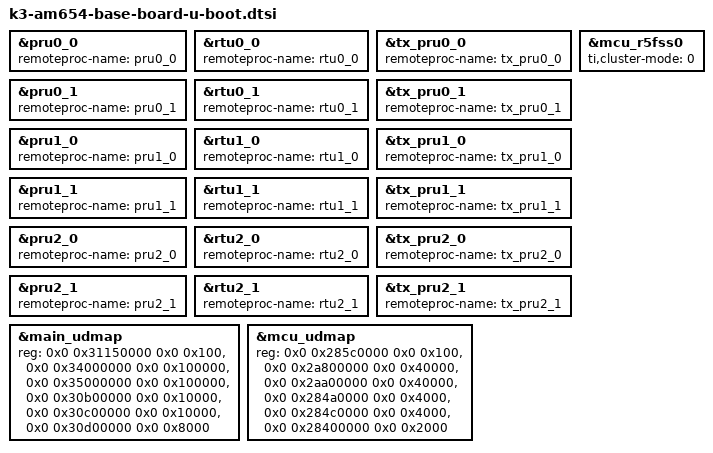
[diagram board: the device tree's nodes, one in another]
// SPDX-License-Identifier: GPL-2.0
/*
 * Copyright (C) 2018-2021 Texas Instruments Incorporated - http://www.ti.com/
 */

#include "k3-am654-r5-base-board-u-boot.dtsi"
#include "k3-am65x-binman.dtsi"

&pru0_0 {
	remoteproc-name = "pru0_0";
};

&rtu0_0 {
	remoteproc-name = "rtu0_0";
};

&tx_pru0_0 {
	remoteproc-name = "tx_pru0_0";
};

&pru0_1 {
	remoteproc-name = "pru0_1";
};

&rtu0_1 {
	remoteproc-name = "rtu0_1";
};

&tx_pru0_1 {
	remoteproc-name = "tx_pru0_1";
};

&pru1_0 {
	remoteproc-name = "pru1_0";
};

&rtu1_0 {
	remoteproc-name = "rtu1_0";
};

&tx_pru1_0 {
	remoteproc-name = "tx_pru1_0";
};

&pru1_1 {
	remoteproc-name = "pru1_1";
};

&rtu1_1 {
	remoteproc-name = "rtu1_1";
};

&tx_pru1_1 {
	remoteproc-name = "tx_pru1_1";
};

&pru2_0 {
	remoteproc-name = "pru2_0";
};

&rtu2_0 {
	remoteproc-name = "rtu2_0";
};

&tx_pru2_0 {
	remoteproc-name = "tx_pru2_0";
};

&pru2_1 {
	remoteproc-name = "pru2_1";
};

&rtu2_1 {
	remoteproc-name = "rtu2_1";
};

&tx_pru2_1 {
	remoteproc-name = "tx_pru2_1";
};

&mcu_r5fss0 {
	ti,cluster-mode = <0>;
};

/*
 * The DMA driver requires a few extra register ranges
 * which are missing for the am65x. A patch has been
 * sent and merged to linux and will be synced with
 * upstream u-boot in the next DT sync.
 */
&main_udmap {
	reg = <0x0 0x31150000 0x0 0x100>,
	      <0x0 0x34000000 0x0 0x100000>,
	      <0x0 0x35000000 0x0 0x100000>,
	      <0x0 0x30b00000 0x0 0x10000>,
	      <0x0 0x30c00000 0x0 0x10000>,
	      <0x0 0x30d00000 0x0 0x8000>;
	reg-names = "gcfg", "rchanrt", "tchanrt",
		    "tchan", "rchan", "rflow";
};

/*
 * The DMA driver requires a few extra register ranges
 * which are missing for the am65x. A patch has been
 * sent and merged to linux and will be synced with
 * upstream u-boot in the next DT sync.
 */
&mcu_udmap {
	reg = <0x0 0x285c0000 0x0 0x100>,
	      <0x0 0x2a800000 0x0 0x40000>,
	      <0x0 0x2aa00000 0x0 0x40000>,
	      <0x0 0x284a0000 0x0 0x4000>,
	      <0x0 0x284c0000 0x0 0x4000>,
	      <0x0 0x28400000 0x0 0x2000>;
	reg-names = "gcfg", "rchanrt", "tchanrt",
		    "tchan", "rchan", "rflow";
};
